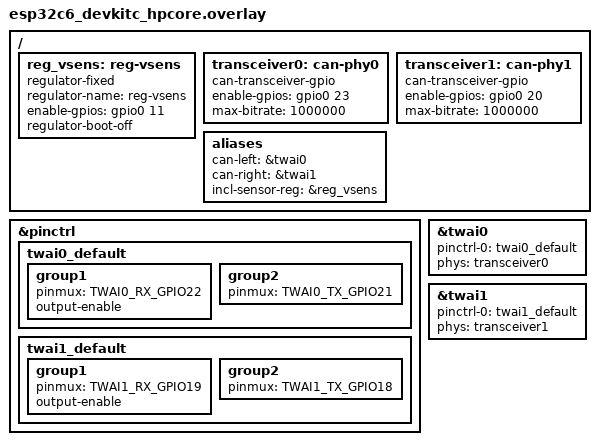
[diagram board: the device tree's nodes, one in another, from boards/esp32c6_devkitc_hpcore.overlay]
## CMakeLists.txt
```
#-------------------------------------------------------------------------------
# Zephyr Example Application
#
# Copyright (c) 2021 Nordic Semiconductor ASA
# SPDX-License-Identifier: Apache-2.0

cmake_minimum_required(VERSION 3.13.1)
find_package(Zephyr REQUIRED HINTS $ENV{ZEPHYR_BASE})

project(app LANGUAGES C)

target_sources(app PRIVATE 
                src/main.c
                src/bt_manager.c
                src/incl_svc.c
                src/sensor_manager.c
                objdict/CO_OD.c)

zephyr_include_directories(objdict)
```

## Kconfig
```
# Copyright (c) 2021 Nordic Semiconductor ASA
# SPDX-License-Identifier: Apache-2.0
#
# This file is the application Kconfig entry point. All application Kconfig
# options can be defined here or included via other application Kconfig files.
# You can browse these options using the west targets menuconfig (terminal) or
# guiconfig (GUI).

menu "Zephyr"
source "Kconfig.zephyr"
endmenu

menu "Pregnancy Patch App"

# config NUM_MANAGED_NET_BUF
# 	int "Number of managed net_buf"
#     default 20
#     range 0 $(UINT16_MAX)
# 	help
# 	  Use this to set maximum number of managed net_buf. Static memory will be allocated.

config INCL_SENSOR_READ_THREAD_PRIO
	int "inclination sensor read thread priority"
	#This priority shall be equal to or higher than ADC_ADS1299_ACQUISITION_WORKQUEUE_PRIO
	#otherwise, it may trigger error on ADC read happens without output buffer
	default 1
	help
	  Priority inclination sensor read thread

config INCL_SENSOR_READ_THREAD_STACK_SIZE
	int "Stack size for the inclination sensor read thread"
	default 1024
	help
	  Size of the stack used for the inclination sensor read thread
   
module = APP
module-str = APP
source "subsys/logging/Kconfig.template.log_config"

endmenu   
```

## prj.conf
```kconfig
##########################
#   APP required features
##########################
CONFIG_SMF=y
CONFIG_ZBUS=y
CONFIG_REGULATOR=y
##########################
#   BT features
##########################
CONFIG_BT=y
#CONFIG_BT_DEBUG_LOG=y
# CONFIG_BT_SMP=n
CONFIG_BT_PERIPHERAL=y
CONFIG_BT_DEVICE_NAME="InclSensor"

##########################
#   CAN bus features
##########################
CONFIG_CAN=y
CONFIG_CANOPEN=y

##########################
#   Shell and Logging
##########################
CONFIG_SHELL=y
CONFIG_LOG=y
CONFIG_APP_LOG_LEVEL_DBG=y
```

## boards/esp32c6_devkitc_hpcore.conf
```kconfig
CONFIG_BT_BUF_EVT_RX_COUNT=16
CONFIG_ESP32_BT_LE_ACL_BUF_COUNT=10
CONFIG_BT_BUF_ACL_TX_COUNT=10
```

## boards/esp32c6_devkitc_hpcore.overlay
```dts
/ {
	reg_vsens: reg-vsens {
		compatible = "regulator-fixed";
		regulator-name = "reg-vsens";
		enable-gpios = <&gpio0 11 GPIO_ACTIVE_HIGH>;
		regulator-boot-off;
		status = "okay";
	};

	transceiver0: can-phy0 {
		compatible = "can-transceiver-gpio";
		enable-gpios = <&gpio0 23 GPIO_ACTIVE_HIGH>;
		max-bitrate = <1000000>;
		#phy-cells = <0>;
	};

	transceiver1: can-phy1 {
		compatible = "can-transceiver-gpio";
		enable-gpios = <&gpio0 20 GPIO_ACTIVE_HIGH>;
		max-bitrate = <1000000>;
		#phy-cells = <0>;
	};

	aliases {
		can-left = &twai0;
        can-right = &twai1;
		incl-sensor-reg = &reg_vsens;
	};
};

&pinctrl {
	twai0_default: twai0_default {
		group1 {
			pinmux = <TWAI0_RX_GPIO22>;
			output-enable;	
		};

		group2 {
			pinmux = <TWAI0_TX_GPIO21>;
		};
	};
	twai1_default: twai1_default {
		group1 {
			pinmux = <TWAI1_RX_GPIO19>;
			output-enable;	
		};

		group2 {
			pinmux = <TWAI1_TX_GPIO18>;
		};
	};
};

&twai0 {
	status = "okay";
	pinctrl-0 = <&twai0_default>;
	pinctrl-names = "default";

	phys = <&transceiver0>;
};

&twai1 {
	status = "okay";
	pinctrl-0 = <&twai1_default>;
	pinctrl-names = "default";

	phys = <&transceiver1>;
};
```

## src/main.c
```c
/*
 * Copyright (c) 2021 Nordic Semiconductor ASA
 * SPDX-License-Identifier: Apache-2.0
 */

#include <zephyr/kernel.h>
#include <zephyr/logging/log.h>
#include <zephyr/smf.h>
#include <zephyr/zbus/zbus.h>

#include <app_version.h>

#include "common.h"

LOG_MODULE_REGISTER(main, CONFIG_APP_LOG_LEVEL);

ZBUS_CHAN_DEFINE(incl_sensor_event_chan,  /* Name */
		 struct incl_sensor_system_event, /* Message type */
		 NULL, /* Validator */
		 NULL, /* User data */
		 ZBUS_OBSERVERS(incl_sensor_event_handler), /* observers */
		 ZBUS_MSG_INIT(.type = EVENT_NONE)		      /* Initial value {0} */
);

//forward declaration
static const struct smf_state incl_sensor_sm_states[];

struct incl_sensor_state_machine{
	struct smf_ctx sm_ctx;
	const struct smf_state *sm_states;
	struct k_msgq* msgq;
	struct incl_sensor_system_event event;
};

/* USB state machine */
K_MSGQ_DEFINE(sm_msgq, sizeof(struct incl_sensor_system_event), 10, 1); 
static struct incl_sensor_state_machine incl_sensor_sm = {.msgq = &sm_msgq, .sm_states = incl_sensor_sm_states};

static void init_entry(void *o)
{
	LOG_DBG("init_entry()");
	int err = start_ble();
	if (err) {
		LOG_ERR("Failed to start BLE");
		//TODO: post error event to state machine
	}

	//TODO: Other initialization such as sensors, adc, etc

    struct incl_sensor_system_event event = {
        .type = EVENT_SYSTEM,
        .system = SYSTEM_INITIATED,
    };
	err = zbus_chan_pub(&incl_sensor_event_chan, &event, K_FOREVER);
	if (err < 0){
		LOG_ERR("zbus_chan_pub(&incl_sensor_event_chan) error (%d)\n", err);
	}	
}

static enum smf_state_result init_run(void *o)
{
	struct incl_sensor_state_machine *sm = CONTAINER_OF(o, struct incl_sensor_state_machine, sm_ctx);
	if(IS_INCL_SENSOR_EVENT(&sm->event, EVENT_SYSTEM, SYSTEM_INITIATED)){
		smf_set_state(&sm->sm_ctx, &incl_sensor_sm_states[APP_STATE_IDLE]);
	}
	else{
		LOG_WRN("Unexpected event %d,%d in init state", sm->event.type, sm->event.ble);
	}
	return SMF_EVENT_HANDLED;
}

static void idle_entry(void *o)
{
	LOG_DBG("init_entry()");
	int err = start_ble_adv();
	if (err) {
		LOG_ERR("Failed to start BLE");
		//TODO: post error event to state machine
	}
}

static enum smf_state_result idle_run(void *o)
{
	struct incl_sensor_state_machine *sm = CONTAINER_OF(o, struct incl_sensor_state_machine, sm_ctx);
	if(IS_INCL_SENSOR_EVENT(&sm->event, EVENT_BLE, BLE_CONNECTED)){
		smf_set_state(&sm->sm_ctx, &incl_sensor_sm_states[APP_STATE_CONNECTED]);
	}
	else{
		LOG_WRN("Unexpected event %d,%d in idle state", sm->event.type, sm->event.ble);
	}
	return SMF_EVENT_HANDLED;
}

static void connected_entry(void *o)
{
	LOG_DBG("connected_entry()");
}

static enum smf_state_result connected_run(void *o)
{
	struct incl_sensor_state_machine *sm = CONTAINER_OF(o, struct incl_sensor_state_machine, sm_ctx);
	if(IS_INCL_SENSOR_EVENT(&sm->event, EVENT_BLE, BLE_DISCONNECTED)){
		smf_set_state(&sm->sm_ctx, &incl_sensor_sm_states[APP_STATE_IDLE]);
	}
	else if(IS_INCL_SENSOR_EVENT(&sm->event, EVENT_BLE, BLE_NOTIFY_ENABLED)){
		smf_set_state(&sm->sm_ctx, &incl_sensor_sm_states[APP_STATE_SENSING]);
	}
	else{
		LOG_WRN("Unexpected event %d,%d in connected state", sm->event.type, sm->event.ble);
	}
	return SMF_EVENT_HANDLED;
}

static void sensing_entry(void *o)
{
	LOG_DBG("sensing_entry()");
	incl_sensor_data_read_start();
}

static enum smf_state_result sensing_run(void *o)
{
	struct incl_sensor_state_machine *sm = CONTAINER_OF(o, struct incl_sensor_state_machine, sm_ctx);
	if(IS_INCL_SENSOR_EVENT(&sm->event, EVENT_BLE, BLE_NOTIFY_DISABLED)){
		smf_set_state(&sm->sm_ctx, &incl_sensor_sm_states[APP_STATE_CONNECTED]);
	}
	else{
		LOG_WRN("Unexpected event %d,%d in sensing state", sm->event.type, sm->event.ble);
	}
	return SMF_EVENT_HANDLED;
}

static void sensing_exit(void *o)
{
	LOG_DBG("sensing_exit()");
	incl_sensor_data_read_stop();
}

static const struct smf_state incl_sensor_sm_states[] = {
        [APP_STATE_INIT] = SMF_CREATE_STATE(init_entry, init_run, NULL, NULL, NULL),
		[APP_STATE_IDLE] = SMF_CREATE_STATE(idle_entry, idle_run, NULL, NULL, NULL),
        [APP_STATE_CONNECTED] = SMF_CREATE_STATE(connected_entry, connected_run, NULL, NULL, NULL),
        [APP_STATE_SENSING] = SMF_CREATE_STATE(sensing_entry, sensing_run, sensing_exit, NULL, NULL),
};

static void incl_sensor_event_cb(const struct zbus_channel *chan)
{
	const struct incl_sensor_system_event *event = zbus_chan_const_msg(chan);
	int err = k_msgq_put(incl_sensor_sm.msgq, event, K_FOREVER);
	if(err){
		LOG_ERR("k_msgq_put() returns %d", err);
	}
}
ZBUS_LISTENER_DEFINE(incl_sensor_event_handler, incl_sensor_event_cb);

int main(void)
{
	int err;
	LOG_INF("PurplePedal App Version: v%u.%u.%u", APP_VERSION_MAJOR, APP_VERSION_MINOR, APP_PATCHLEVEL);

	smf_set_initial(&incl_sensor_sm.sm_ctx, &incl_sensor_sm_states[APP_STATE_INIT]);
	while(1){
		//k_msleep(1000);
		err = k_msgq_get(incl_sensor_sm.msgq, &incl_sensor_sm.event, K_FOREVER);
		if(err == 0){
			err = smf_run_state(&incl_sensor_sm.sm_ctx);
			if(err){
				LOG_INF("%s terminating state machine thread", __func__);
				break;
			}
		}
		else{
			LOG_ERR("k_msgq_get() returns %d", err);
		}
	}
	return 0;
}
```

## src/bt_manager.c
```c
#include <zephyr/logging/log.h>
LOG_MODULE_REGISTER(bt_manager, CONFIG_APP_LOG_LEVEL);

#include <zephyr/bluetooth/bluetooth.h>
#include <zephyr/bluetooth/conn.h>
#include <zephyr/bluetooth/gatt.h>
#include <zephyr/bluetooth/hci.h>
#include <zephyr/zbus/zbus.h>

#include "common.h"
#include "incl_svc.h"

ZBUS_CHAN_DECLARE(incl_sensor_event_chan);

static struct bt_conn *default_conn = NULL;

static void connected(struct bt_conn *conn, uint8_t err)
{
	char addr[BT_ADDR_LE_STR_LEN];

	bt_addr_le_to_str(bt_conn_get_dst(conn), addr, sizeof(addr));

	if (default_conn == NULL) {
		default_conn = bt_conn_ref(conn);
	}

	if (conn != default_conn) {
		return;
	}

    LOG_INF("BT Connected: %s\n", addr);

    struct incl_sensor_system_event event = {
        .type = EVENT_BLE,
        .ble = BLE_CONNECTED,
    };
	err = zbus_chan_pub(&incl_sensor_event_chan, &event, K_FOREVER);
	if (err < 0){
		LOG_ERR("zbus_chan_pub(&incl_sensor_event_chan) error (%d)\n", err);
	}
	
}

static void disconnected(struct bt_conn *conn, uint8_t reason)
{
	char addr[BT_ADDR_LE_STR_LEN];

	if (conn != default_conn) {
		return;
	}

	bt_addr_le_to_str(bt_conn_get_dst(conn), addr, sizeof(addr));

	LOG_INF("Disconnected: %s, reason 0x%02x %s\n", addr, reason, bt_hci_err_to_str(reason));

	bt_conn_unref(default_conn);
	default_conn = NULL;

    struct incl_sensor_system_event event = {
        .type = EVENT_BLE,
        .ble = BLE_DISCONNECTED,
    };
	int err = zbus_chan_pub(&incl_sensor_event_chan, &event, K_FOREVER);
	if (err < 0){
		LOG_ERR("zbus_chan_pub(&incl_sensor_event_chan) error (%d)\n", err);
	}
}

static struct bt_conn_cb conn_callbacks = {
	.connected = connected,
	.disconnected = disconnected,
};

static void mtu_updated(struct bt_conn *conn, uint16_t tx, uint16_t rx)
{
	LOG_INF("Updated MTU: TX: %d RX: %d bytes\n", tx, rx);
}

static struct bt_gatt_cb gatt_callbacks = {.att_mtu_updated = mtu_updated};

static void ble_auth_cancel_cb(struct bt_conn *conn)
{
	char addr[BT_ADDR_LE_STR_LEN];

	bt_addr_le_to_str(bt_conn_get_dst(conn), addr, sizeof(addr));
	LOG_INF("BLE Pairing cancelled: %s\n", addr);
}

static struct bt_conn_auth_cb ble_auth_cb_display = {
	.cancel = ble_auth_cancel_cb
};


void incl_svc_notify_enabled_cb(bool enabled, void *ctx)
{
    LOG_INF("incl_svc_notify_enabled_cb: enabled=%d\n", enabled);
    if(enabled){
        struct incl_sensor_system_event event = {
            .type = EVENT_BLE,
            .ble = BLE_NOTIFY_ENABLED,
        };
        int err = zbus_chan_pub(&incl_sensor_event_chan, &event, K_FOREVER);
        if (err < 0){
            LOG_ERR("zbus_chan_pub(&incl_sensor_event_chan) error (%d)\n", err);
        }
    }
    else{
        struct incl_sensor_system_event event = {
            .type = EVENT_BLE,
            .ble = BLE_NOTIFY_DISABLED,
        };
        int err = zbus_chan_pub(&incl_sensor_event_chan, &event, K_FOREVER);
        if (err < 0){
            LOG_ERR("zbus_chan_pub(&incl_sensor_event_chan) error (%d)\n", err);
        }
    }
}

struct bt_incl_svc_cb incl_svc_callbacks = {
    .notify_enabled = incl_svc_notify_enabled_cb, 
    .ctx = NULL,
};

int start_ble(void)
{
    LOG_INF("Startup Bluetooth\n");
	int err = bt_enable(NULL);
	if (err) {
		LOG_ERR("bt_enable() returns error %d", err);
        return err;
	}
    bt_conn_cb_register(&conn_callbacks);
	bt_gatt_cb_register(&gatt_callbacks);
    incl_svc_cb_register(&incl_svc_callbacks);

    return 0;
}

static const struct bt_data ad[] = {
	BT_DATA_BYTES(BT_DATA_FLAGS, (BT_LE_AD_GENERAL | BT_LE_AD_NO_BREDR)),
	BT_DATA_BYTES(BT_DATA_UUID128_ALL, BT_UUID_INCL_SVC_VAL),
    BT_DATA(BT_DATA_NAME_COMPLETE, CONFIG_BT_DEVICE_NAME, sizeof(CONFIG_BT_DEVICE_NAME) - 1),
};

static void adv_restart_fn(struct k_work *work)
{
    int err = bt_le_adv_start(BT_LE_ADV_CONN_FAST_1, ad, ARRAY_SIZE(ad), NULL, 0);
    if (err) {
		LOG_ERR("BLE Advertising failed to start (error %d)\n", err);
        return;
	} else {
		LOG_INF("BLE Advertising started");
#if defined(CONFIG_BT_SMP)
        bt_conn_auth_cb_register(&ble_auth_cb_display);
#endif
    }
    // struct incl_sensor_system_event event = {
    //     .type = EVENT_BLE,
    //     .ble = BLE_ADV_STARTED,
    // };
	// err = zbus_chan_pub(&incl_sensor_event_chan, &event, K_FOREVER);
	// if (err < 0){
	// 	LOG_ERR("zbus_chan_pub(&incl_sensor_event_chan) error (%d)\n", err);
	// }	
}

K_WORK_DELAYABLE_DEFINE(adv_restart_work, adv_restart_fn);

int start_ble_adv(void)
{
    LOG_INF("Start Bluetooth Advertising\n");
    //intentional delay to avoid immediately starting adv
    //right after a connection is disconnected
    int err =k_work_schedule(&adv_restart_work, K_MSEC(100));
    if(err < 0){
        LOG_ERR("k_work_schedule() returns error %d", err);
        return err;
    }
    return 0;
}

static void incl_sensor_data_read_cb(const struct zbus_channel *chan)
{
	const struct incl_sensor_system_data *data = zbus_chan_const_msg(chan);
    //send BLE notification
    incl_svc_send_data(data);
}
ZBUS_LISTENER_DEFINE(incl_sensor_data_read_handler, incl_sensor_data_read_cb);
```

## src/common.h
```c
#ifndef COMMON_H
#define COMMON_H

#ifdef __cplusplus
extern "C" {
#endif

#include <stdint.h>

enum app_state{
	APP_STATE_INIT=0,
	APP_STATE_IDLE,
	APP_STATE_CONNECTED,
	APP_STATE_SENSING,
	APP_STATE_NUM,
};

enum incl_sensor_event_type{
	EVENT_NONE=0,
	EVENT_BLE,
	EVENT_SYSTEM,
    EVNET_SENSOR,
};

enum incl_sensor_ble_event_type{
	BLE_CONNECTED,
	BLE_DISCONNECTED,
	BLE_NOTIFY_ENABLED,
	BLE_NOTIFY_DISABLED,
};

enum inc_sensor_system_event_type{
	SYSTEM_INITIATED,
	SYSTEM_ERROR,
};

struct incl_sensor_system_event{
	enum incl_sensor_event_type type;
	union{
		enum incl_sensor_ble_event_type ble;
		enum inc_sensor_system_event_type system;
	};
};

#define IS_INCL_SENSOR_EVENT(event_ptr, ev_type, ev_subtype) \
    ((event_ptr)->type == (ev_type) && ( \
        ((ev_type) == EVENT_BLE) ? ((event_ptr)->ble == (enum incl_sensor_ble_event_type)(ev_subtype)) : \
        ((ev_type) == EVENT_SYSTEM) ? ((event_ptr)->system == (enum inc_sensor_system_event_type)(ev_subtype)) : false \
    ))

struct incl_sensor_system_data{
	int16_t left_x;
	int16_t left_y;
	int16_t right_x;
	int16_t right_y;
	int16_t error_code;
}__packed;

int start_ble(void);
int start_ble_adv(void);

void incl_sensor_data_read_start(void);
void incl_sensor_data_read_stop(void);

#ifdef __cplusplus
}
#endif

#endif /* COMMON_H */
```

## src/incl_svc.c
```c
#include <zephyr/bluetooth/conn.h>
#include <zephyr/bluetooth/uuid.h>
#include <zephyr/bluetooth/gatt.h>

#include <zephyr/logging/log.h>
LOG_MODULE_REGISTER(incl_svc, CONFIG_APP_LOG_LEVEL);

#include "common.h"
#include "incl_svc.h"

//single linked list of callbacks, if there is a need for context,
//this can be put into a big context struct
static sys_slist_t incl_svc_cbs = SYS_SLIST_STATIC_INIT(&incl_svc_cbs);

static void incl_svc_ccc_cfg_changed(const struct bt_gatt_attr *attr, uint16_t value)
{
    //see example implementation in 
    //https://github.com/nrfconnect/sdk-nrf/blob/main/subsys/bluetooth/services/nus.c#L18
    //https://github.com/zephyrproject-rtos/zephyr/blob/69a8ac6a020d19d76c6fb6155072b5573f5e0013/subsys/bluetooth/services/nus/nus.c
	struct bt_incl_svc_cb *listener;
	SYS_SLIST_FOR_EACH_CONTAINER(&incl_svc_cbs, listener, _node) {
		if (listener->notify_enabled) {
			listener->notify_enabled((value == 1), listener->ctx);
		}
	}	
}

BT_GATT_SERVICE_DEFINE(incl_svc,
BT_GATT_PRIMARY_SERVICE(BT_UUID_INCL_SVC),
	BT_GATT_CHARACTERISTIC(BT_UUID_INCL_SVC_RPT,
			       BT_GATT_CHRC_NOTIFY,
			       BT_GATT_PERM_READ,
			       NULL, NULL, NULL),
	BT_GATT_CCC(incl_svc_ccc_cfg_changed,
			       BT_GATT_PERM_READ | BT_GATT_PERM_WRITE),

);

#define GATT_CHARACTERISTIC_INDEX_INCL_SENSOR_RPT (1)

int incl_svc_cb_register(struct bt_incl_svc_cb *cb)
{
	if(!cb || !cb->notify_enabled){
		return -EINVAL;
	}
	sys_slist_append(&incl_svc_cbs, &cb->_node);
	return 0;
}

int incl_svc_send_data(const struct incl_sensor_system_data *data)
{	
	if(!data){
		return -EINVAL;
	}
	int err = bt_gatt_notify(NULL, &incl_svc.attrs[GATT_CHARACTERISTIC_INDEX_INCL_SENSOR_RPT], data, sizeof(struct incl_sensor_system_data));
	if(err){
		LOG_ERR("bt_gatt_notify() returns %d", err);
	}
	return err;
}
```

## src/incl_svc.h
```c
#ifndef INCL_SVC_H
#define INCL_SVC_H

#ifdef __cplusplus
extern "C" {
#endif

/** @brief UUID of the NUS Service. **/
#define BT_UUID_INCL_SVC_VAL \
	BT_UUID_128_ENCODE(0x073c0000, 0xfd08, 0x42d9, 0xbdc9, 0x7f63a3a3ee5c)

/** @brief UUID of the TX Characteristic. **/
#define BT_UUID_INCL_SVC_RPT_VAL \
	BT_UUID_128_ENCODE(0x073c0001, 0xfd08, 0x42d9, 0xbdc9, 0x7f63a3a3ee5c)


#define BT_UUID_INCL_SVC   BT_UUID_DECLARE_128(BT_UUID_INCL_SVC_VAL)
#define BT_UUID_INCL_SVC_RPT        BT_UUID_DECLARE_128(BT_UUID_INCL_SVC_RPT_VAL)

/** @brief GHSS callbacks */
struct bt_incl_svc_cb{
	/** @brief Notifications subscription changed
	 *
	 * @param enabled Flag that is true if notifications were enabled, false
	 *                if they were disabled.
	 * @param ctx User context provided in the callback structure.
	 */
	void (*notify_enabled)(bool enabled, void *ctx);

	/** @brief Received Data
	 *
	 * @param conn Peer Connection object.
	 * @param data Pointer to buffer with data received.
	 * @param len Size in bytes of data received.
	 * @param ctx User context provided in the callback structure.
	 */
	//void (*received)(struct bt_conn *conn, const void *data, uint16_t len, void *ctx);

	/** Internal member. Provided as a callback argument for user context */
	void *ctx;

    /** Internal member to form a list of callbacks */
	sys_snode_t _node;
};

int incl_svc_cb_register(struct bt_incl_svc_cb *cb);
int incl_svc_send_data(const struct incl_sensor_system_data *data);

#ifdef __cplusplus
}
#endif

#endif /* INCL_SVC_H */
```

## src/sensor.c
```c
#include <zephyr/zbus/zbus.h>
#include <zephyr/smf.h>

#include <zephyr/logging/log.h>
LOG_MODULE_REGISTER(sensor, CONFIG_APP_LOG_LEVEL);

#include "sensor.h"


static void init_entry(void *o)
{
    LOG_DBG("init_entry()");

}

static enum smf_state_result init_run(void *o)
{
	struct incl_sensor_context *ctx = CONTAINER_OF(o, struct incl_sensor_context, sm_ctx);
    //periodically sending RTR frame and monitor bootup or guarding message
    //if we receive expected message, transition to pre-operational state
    //we don't block on waiting CAN message here,
    //give CAN bus filter and trigger event in callback
	return SMF_EVENT_HANDLED;
}

static const struct smf_state incl_sensor_sm_states[] = {
        [INCL_SENSOR_INIT] = SMF_CREATE_STATE(init_entry, init_run, NULL, NULL, NULL),
};

void incl_sensor_task(void *p1, void *p2, void *p3)
{
    //run a state machine, 
    struct incl_sensor_context *ctx = (struct incl_sensor_context*)p1;
    smf_set_initial(&ctx->sm_ctx, &ctx->sm_states[INCL_SENSOR_INIT]);

}

void incl_sensor_init(struct incl_sensor_context *ctx)
{
    //send trigger message to state machine
}

void incl_sensor_read(struct incl_sensor_context *ctx)
{

}

void incl_sensor_stop(struct incl_sensor_context *ctx)
{
    //send trigger message to state machine
}
```

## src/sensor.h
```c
#ifndef SENSOR_H
#define SENSOR_H

#ifdef __cplusplus
extern "C" {
#endif

#include <zephyr/smf.h>

enum incl_sensor_state{
    INCL_SENSOR_INIT = 0,
    INCL_SENSOR_PRE_OPERATIONAL,
    INCL_SENSOR_OPERATIONAL,
    INCL_SENSOR_STOPPED,
    INCL_SENSOR_ERROR,
};

enum inc_sensor_ctrl_event_type{
	INCL_SENSOR_START,
	INCL_SENSOR_STOP,
};

struct incl_sensor_context{
    const struct device *dev;
    struct smf_ctx sm_ctx;
    const struct smf_state *sm_states;
    struct k_msgq* msgq;
    enum inc_sensor_ctrl_event_type event;
};
struct incl_sensor_data{
    int16_t x;
    int16_t y;
};

struct incl_sensor_cb{
    void (*sensor_operational)(struct incl_sensor_context* ctx);
    void (*data_ready)(const struct incl_sensor_data* data, struct incl_sensor_context* ctx);
    void (*error)(int error_code, struct incl_sensor_context* ctx);
    struct incl_sensor_context *ctx;
};

void incl_sensor_task(void *p1, void *p2, void *p3);

#define INCL_SENSOR_CONTEXT_DEFINE(name, can) \
    K_MSGQ_DEFINE(name##_msgq, sizeof(enum inc_sensor_ctrl_event_type), 10, 1); \
    const struct smf_state name##_sm_states[]; \
    K_THREAD_STACK_DEFINE(name##_thread_stack, CONFIG_INCL_SENSOR_THREAD_STACK_SIZE); \
     struct incl_sensor_context name##_ctx; \
    void name##_thread_fn(void *p1, void *p2, void *p3); \
    K_THREAD_DEFINE(name##_thread_id, CONFIG_INCL_SENSOR_THREAD_STACK_SIZE, name##_thread_fn, &name##_ctx, NULL, NULL, CONFIG_INCL_SENSOR_THREAD_PRIO, 0, 0);

void incl_sensor_init(struct incl_sensor_context *ctx);
void incl_sensor_read(struct incl_sensor_context *ctx);
void incl_sensor_stop(struct incl_sensor_context *ctx);

#ifdef __cplusplus
}
#endif

#endif /* SENSOR_H */
```

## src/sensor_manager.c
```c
#include <zephyr/kernel.h>
#include <zephyr/drivers/regulator.h>
#include <zephyr/drivers/can.h>
#include <zephyr/zbus/zbus.h>
#include <zephyr/smf.h>

#include <zephyr/logging/log.h>
LOG_MODULE_REGISTER(sensor_manager, CONFIG_APP_LOG_LEVEL);

#include "common.h"

enum incl_sensor_index{
    INCL_SENSOR_LEFT = 0,
    INCL_SENSOR_RIGHT,
    INCL_SENSOR_NUM,
};

enum incl_sensor_state{
    INCL_SENSOR_OFF = 0,
    INCL_SENSOR_INIT,
    INCL_SENSOR_PRE_OPERATIONAL,
    INCL_SENSOR_OPERATIONAL,
    INCL_SENSOR_STOPPED,
    INCL_SENSOR_ERROR, //TODO: this one maybe not needed
};

enum inc_sensor_ctrl_event_type{
    INCL_SENSOR_EVENT_NONE = 0,
	INCL_SENSOR_CMD_START,
	INCL_SENSOR_CMD_STOP,
    INCL_SENSOR_EVENT_CAN_TIMEOUT,
};

enum incl_sensor_canbus_filter_type{
    CAN_FILTER_TPDO1 = 0,
    CAN_FILTER_EMERGENCY,
    CAN_FILTER_NMT_ERR_CTRL,
    CAN_FILTER_NUM,
};

enum incl_sensor_canbus_send_frame_type{
    INCL_SENSOR_CAN_FRAME_RTR = 0,
    INCL_SENSOR_CAN_FRAME_NMT_START_REMOTE_NODE,
    INCL_SENSOR_CAN_FRAME_SYNC,
    INCL_SENSOR_CAN_FRAME_NUM,
};
const struct can_filter incl_sensor_canbus_filter[CAN_FILTER_NUM] = {
    [CAN_FILTER_TPDO1] = {
        .id = 0x180, //TODO: confirm the ID
        .mask = CAN_STD_ID_MASK,
        .flags = 0U,
    },
    [CAN_FILTER_EMERGENCY] = {
        .id = 0x80, //TODO: confirm the ID
        .mask = CAN_STD_ID_MASK,
        .flags = 0U,
    },
    [CAN_FILTER_NMT_ERR_CTRL] = {
        .id = 0x700, //TODO: confirm the ID
        .mask = CAN_STD_ID_MASK,
        .flags = 0U,
    },
};

struct can_frame incl_sensor_canbus_frame[INCL_SENSOR_CAN_FRAME_NUM] = {
//Identifier (COB-ID): 0x700 + Node-ID
// Message Type: RTR (Remote Frame, DLC = 0), RTR bit set to 1
// Example: If the sensor's Node-ID is 5, send an RTR to 0x705.
    [INCL_SENSOR_CAN_FRAME_RTR] = {
        .id = 0x180, //TODO: confirm the ID
        .dlc = 0,
        .flags = CAN_FRAME_RTR,
    },
    [INCL_SENSOR_CAN_FRAME_NMT_START_REMOTE_NODE] = {
        .id = 0x000, //NMT frame has ID 0
        .dlc = 2,
        .data = {0x01, 0x00}, //Start remote node with ID 0 (broadcast)
    },
    [INCL_SENSOR_CAN_FRAME_SYNC] = {
        .id = 0x80, //TODO: confirm the ID
        .dlc = 0,
    },
};

const k_timeout_t incl_sensor_canbus_frame_period[INCL_SENSOR_CAN_FRAME_NUM] = {
    [INCL_SENSOR_CAN_FRAME_RTR] = K_MSEC(1000), //TODO: confirm the period
    [INCL_SENSOR_CAN_FRAME_NMT_START_REMOTE_NODE] = K_MSEC(1000), //NMT frame is sent once
    [INCL_SENSOR_CAN_FRAME_SYNC] = K_MSEC(1000), //TODO: confirm the period
};
struct incl_sensor_canbus_context{
    const struct device *dev;
    struct can_filter *filter;
    int filter_id[CAN_FILTER_NUM];
    struct k_msgq *	msgq;
};

struct incl_sensor_context{
    const struct device *reg_vsens;
	// const struct device *dev_left;
    // const struct device *dev_right;
    //TODO: use incl_sensor_canbus_context ?
    //struct k_sem sem;
    const struct device *const dev_can[INCL_SENSOR_NUM];
    struct k_msgq *const can_msgq[INCL_SENSOR_NUM];
    const struct can_filter *const can_ft;
    const struct can_frame *const can_frm;
    const k_timeout_t *const can_frm_period;
    int filter_id[INCL_SENSOR_NUM][CAN_FILTER_NUM];
    struct k_timer *can_timer;
    struct smf_ctx sm_ctx;
    const struct smf_state *sm_states;
    struct k_msgq* msgq;
    enum inc_sensor_ctrl_event_type event;
} ;

ZBUS_CHAN_DEFINE(incl_sensor_data_read_chan,  /* Name */
		 struct incl_sensor_system_data, /* Message type */
		 NULL, /* Validator */
		 NULL, /* User data */
		 ZBUS_OBSERVERS(incl_sensor_data_read_handler), /* observers */
		 ZBUS_MSG_INIT(.left_x = 0, .left_y = 0, .right_x = 0, .right_y = 0, .error_code = 0) /* Initial value {0} */
);

static const struct smf_state incl_sensor_sm_states[]; //forward declaration
static void can_timer_expiry_func(struct k_timer *timer_id); //forward declaration
CAN_MSGQ_DEFINE(can_msgq_left, 4);
CAN_MSGQ_DEFINE(can_msgq_right, 4);
K_TIMER_DEFINE(can_tmr, can_timer_expiry_func, NULL);
K_MSGQ_DEFINE(incl_sensor_sm_msgq, sizeof(enum inc_sensor_ctrl_event_type), 10, 1); 
static struct incl_sensor_context ctx = {
    .reg_vsens = DEVICE_DT_GET(DT_ALIAS(incl_sensor_reg)),
    // .dev_left = DEVICE_DT_GET(DT_ALIAS(can_left)),
    // .dev_right = DEVICE_DT_GET(DT_ALIAS(can_right)),
    //.sem = Z_SEM_INITIALIZER(ctx.sem, 0, 1),
    .dev_can = {DEVICE_DT_GET(DT_ALIAS(can_left)), DEVICE_DT_GET(DT_ALIAS(can_right))},
    .can_ft = incl_sensor_canbus_filter,
    .can_msgq = {&can_msgq_left, &can_msgq_right},
    .can_frm = incl_sensor_canbus_frame,
    .can_frm_period = incl_sensor_canbus_frame_period,
    .filter_id = {{-EINVAL, -EINVAL, -EINVAL}, {-EINVAL, -EINVAL, -EINVAL}},
    .can_timer = &can_tmr,
    .msgq = &incl_sensor_sm_msgq,
    .sm_states = incl_sensor_sm_states,
    .event = INCL_SENSOR_EVENT_NONE,
};

////////////////////////////////////////
/* operations needed by state machine */
////////////////////////////////////////
static void start_can(struct incl_sensor_context *ctx)
{
    for(int i = 0; i < INCL_SENSOR_NUM; i++){
        int err = can_set_mode(ctx->dev_can[i], CAN_MODE_NORMAL);
        if(err){
            LOG_ERR("can_set_mode() returns %d for sensor %d", err, i);
        }
        err = can_start(ctx->dev_can[i]);
        if(err){
            LOG_ERR("can_start() returns %d for sensor %d", err, i);
        }
    }
}

static void stop_can(struct incl_sensor_context *ctx)
{
    for(int i = 0; i < INCL_SENSOR_NUM; i++){
        can_stop(ctx->dev_can[i]);
    }
}

static void set_can_filter(struct incl_sensor_context *ctx)
{
    for(int i = 0; i < INCL_SENSOR_NUM; i++){
        for(int j = 0; j < CAN_FILTER_NUM; j++){
            if(ctx->filter_id[i][j] >= 0){
                continue; //filter already set
            }
            int err = can_add_rx_filter_msgq(ctx->dev_can[i], ctx->can_msgq[i], &incl_sensor_canbus_filter[j]);
            if(err < 0){
                LOG_ERR("can_add_rx_filter_msgq() returns %d for sensor %d filter %d", err, i, j);
            }
            else{
                ctx->filter_id[i][j] = err;
            }
        }
    }
}

static void remove_can_filter(struct incl_sensor_context *ctx)
{
    for(int i = 0; i < INCL_SENSOR_NUM; i++){
        for(int j = 0; j < CAN_FILTER_NUM; j++){
            if(ctx->filter_id[i][j] >= 0){
                can_remove_rx_filter(ctx->dev_can[i], ctx->filter_id[i][j]);
                ctx->filter_id[i][j] = -EINVAL;
            }
        }
    }
}

static void can_timer_start(struct incl_sensor_context *ctx, k_timeout_t duration, k_timeout_t period)
{
    k_timer_user_data_set(ctx->can_timer, ctx);
    k_timer_start(ctx->can_timer, duration, period);
}

static void can_timer_expiry_func(struct k_timer *timer_id)
{
    struct incl_sensor_context *ctx = (struct incl_sensor_context *)k_timer_user_data_get(timer_id);
    enum inc_sensor_ctrl_event_type event = INCL_SENSOR_EVENT_CAN_TIMEOUT;
    int err = k_msgq_put(ctx->msgq, &event, K_FOREVER);
	if(err){
		LOG_ERR("k_msgq_put() returns %d", err);
	}
}

static void send_can_frame(struct incl_sensor_context *ctx, enum incl_sensor_canbus_send_frame_type type)
{
    for(int i = 0; i < INCL_SENSOR_NUM; i++){
        int err = can_send(ctx->dev_can[i], &ctx->can_frm[type], K_NO_WAIT, NULL, NULL);
        if(err){
            LOG_ERR("can_send() returns %d for frame %d", err, i);
        }
    }

    can_timer_start(ctx, ctx->can_frm_period[type], K_NO_WAIT); //only trigger the timer once
}

/////////////////////////////
/* state machine functions */
/////////////////////////////
static void off_entry(void *o)
{
    LOG_DBG("off_entry()");
    struct incl_sensor_context *ctx = CONTAINER_OF(o, struct incl_sensor_context, sm_ctx);
    //turn off the regulator
    if(regulator_is_enabled(ctx->reg_vsens)){
        regulator_disable(ctx->reg_vsens);
    }

}

static enum smf_state_result off_run(void *o)
{
	struct incl_sensor_context *ctx = CONTAINER_OF(o, struct incl_sensor_context, sm_ctx);
    if(ctx->event == INCL_SENSOR_CMD_START){
        smf_set_state(&ctx->sm_ctx, &incl_sensor_sm_states[INCL_SENSOR_INIT]);
    }
    else{
        LOG_WRN("Unexpected event %d in off state", ctx->event);
    }
	return SMF_EVENT_HANDLED;
}

static void init_entry(void *o)
{
    LOG_DBG("init_entry()");
    struct incl_sensor_context *ctx = CONTAINER_OF(o, struct incl_sensor_context, sm_ctx);
    //turn on the regulator
    if(!regulator_is_enabled (ctx->reg_vsens)){
        regulator_enable(ctx->reg_vsens);
    }

    start_can(ctx);
    set_can_filter(ctx);
    send_can_frame(ctx, INCL_SENSOR_CAN_FRAME_RTR);
}

static enum smf_state_result init_run(void *o)
{
	struct incl_sensor_context *ctx = CONTAINER_OF(o, struct incl_sensor_context, sm_ctx);
    //periodically sending RTR frame and monitor bootup or guarding message
    //if we receive expected message, transition to pre-operational state
    //we don't block on waiting CAN message here,
    //give CAN bus filter and trigger event in callback
    if(ctx->event == INCL_SENSOR_EVENT_CAN_TIMEOUT){
        //check the ready signal from CAN message queue, if not ready, keep sending RTR frame
        send_can_frame(ctx, INCL_SENSOR_CAN_FRAME_RTR);
    }
    else{
        LOG_WRN("Unexpected event %d in init state", ctx->event);
    }
	return SMF_EVENT_HANDLED;
}

static void pre_operational_entry(void *o)
{
    LOG_DBG("pre_operational_entry()");
    struct incl_sensor_context *ctx = CONTAINER_OF(o, struct incl_sensor_context, sm_ctx);
    send_can_frame(ctx, INCL_SENSOR_CAN_FRAME_NMT_START_REMOTE_NODE);
    send_can_frame(ctx, INCL_SENSOR_CAN_FRAME_RTR);
}

static enum smf_state_result pre_operational_run(void *o)
{
    struct incl_sensor_context *ctx = CONTAINER_OF(o, struct incl_sensor_context, sm_ctx);
    if(ctx->event == INCL_SENSOR_EVENT_CAN_TIMEOUT){
        //check the TPDO1 message from CAN message queue, if not received, keep sending NMT start frame
        send_can_frame(ctx, INCL_SENSOR_CAN_FRAME_NMT_START_REMOTE_NODE);
        send_can_frame(ctx, INCL_SENSOR_CAN_FRAME_RTR);
    }
    else{
        LOG_WRN("Unexpected event %d in pre-operational state", ctx->event);
    }
    return SMF_EVENT_HANDLED;
}

static void operational_entry(void *o)
{
    LOG_DBG("operational_entry()");
    struct incl_sensor_context *ctx = CONTAINER_OF(o, struct incl_sensor_context, sm_ctx);
    send_can_frame(ctx, INCL_SENSOR_CAN_FRAME_SYNC);
}
static enum smf_state_result operational_run(void *o)
{
    struct incl_sensor_context *ctx = CONTAINER_OF(o, struct incl_sensor_context, sm_ctx);
    if(ctx->event == INCL_SENSOR_EVENT_CAN_TIMEOUT){
        //check the TPDO1 message from CAN message queue, if not received, keep sending SYNC frame
        send_can_frame(ctx, INCL_SENSOR_CAN_FRAME_SYNC);
    }
    else{
        LOG_WRN("Unexpected event %d in operational state", ctx->event);
    }
    return SMF_EVENT_HANDLED;
}

static const struct smf_state incl_sensor_sm_states[] = {
    [INCL_SENSOR_OFF] = SMF_CREATE_STATE(off_entry, off_run, NULL, NULL, NULL),
    [INCL_SENSOR_INIT] = SMF_CREATE_STATE(init_entry, init_run, NULL, NULL, NULL),
    [INCL_SENSOR_PRE_OPERATIONAL] = SMF_CREATE_STATE(pre_operational_entry, pre_operational_run, NULL, NULL, NULL),
    [INCL_SENSOR_OPERATIONAL] = SMF_CREATE_STATE(operational_entry, operational_run, NULL, NULL, NULL),
};

// static void incl_sensor_read_task_old(void *p1, void *p2, void *p3)
// {
//     //TODO: Initialize CANopenNode and sensors
//     while(1){
//         k_sem_take(&ctx.sem, K_FOREVER);
//         //TODO: read sensor
//         struct incl_sensor_system_data data = {
//             .left_x = 0,
//             .left_y = 0,
//             .right_x = 0,
//             .right_y = 0,
//             .error_code = 0,
//         };
//         int err = zbus_chan_pub(&incl_sensor_data_read_chan, &data, K_FOREVER);
//         if(err){
//             LOG_ERR("zbus_chan_pub() returns %d", err); 
//         }

//     }

// }

static void incl_sensor_sm_task(void *p1, void *p2, void *p3)
{
    struct incl_sensor_context *ctx = (struct incl_sensor_context*)p1;
    smf_set_initial(&ctx->sm_ctx, &ctx->sm_states[INCL_SENSOR_OFF]);
    while(1){
        enum inc_sensor_ctrl_event_type event;
        int err = k_msgq_get(ctx->msgq, &event, K_FOREVER);
        if(err){
            LOG_ERR("k_msgq_get() returns %d", err); 
            continue;
        }
        ctx->event = event;
        smf_run_state(&ctx->sm_ctx);
    }
}

K_THREAD_DEFINE(incl_sensor_read_thread_id, 
            CONFIG_INCL_SENSOR_READ_THREAD_STACK_SIZE, 
            incl_sensor_sm_task, 
            &ctx, NULL, NULL, 
            CONFIG_INCL_SENSOR_READ_THREAD_PRIO, 
            0, 0);

// static void incl_sensor_data_read_timer_handler(struct k_timer *timer)
// {
// 	struct incl_sensor_context *ctx = (struct incl_sensor_context *)k_timer_user_data_get(timer);
// 	k_sem_give(&ctx->sem);
// }
// static K_TIMER_DEFINE(incl_sensor_data_read_timer, incl_sensor_data_read_timer_handler, NULL);

void incl_sensor_data_read_start(void)
{
    enum inc_sensor_ctrl_event_type event = INCL_SENSOR_CMD_START;
    int err = k_msgq_put(ctx.msgq, &event, K_FOREVER);
	if(err){
		LOG_ERR("k_msgq_put() returns %d", err);
	}
}

void incl_sensor_data_read_stop(void)
{
    enum inc_sensor_ctrl_event_type event = INCL_SENSOR_CMD_STOP;
    int err = k_msgq_put(ctx.msgq, &event, K_FOREVER);
	if(err){
		LOG_ERR("k_msgq_put() returns %d", err);
	}
}
```
